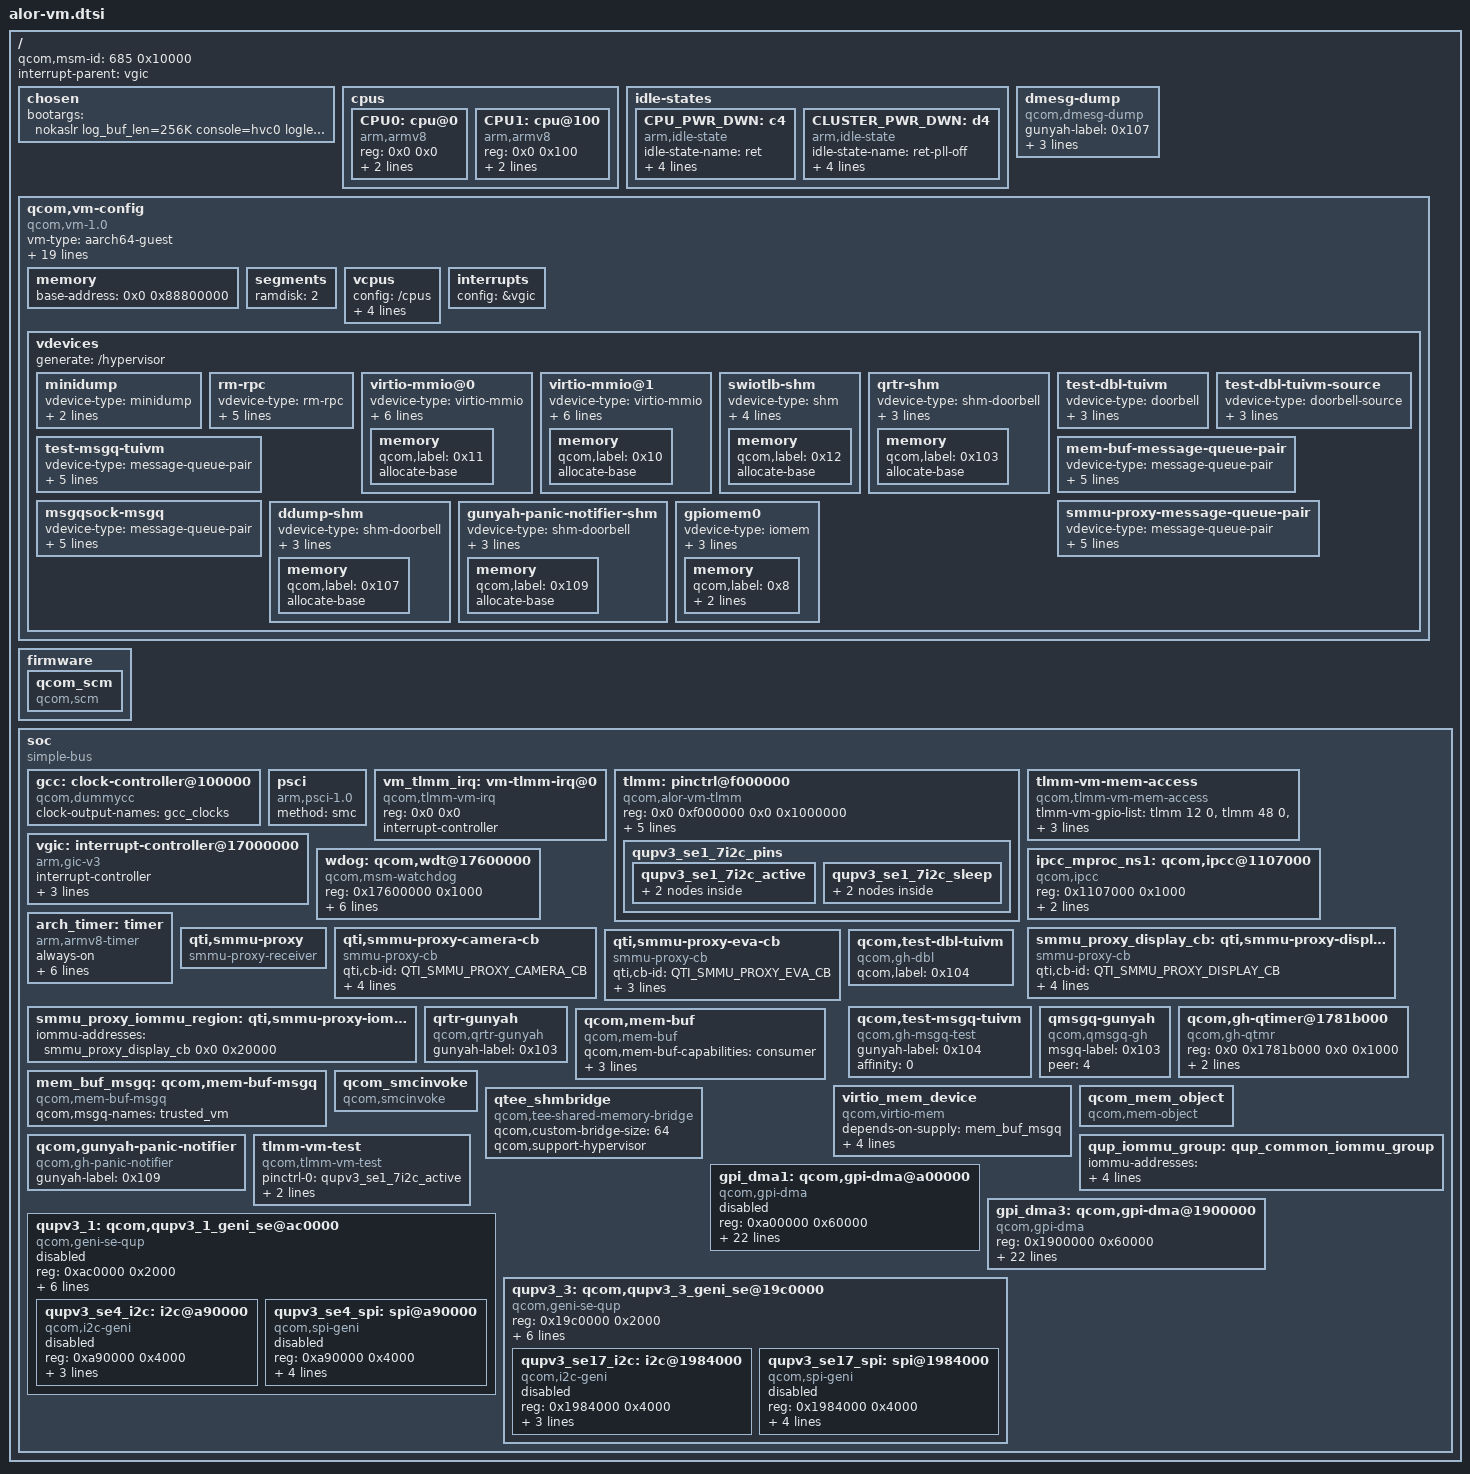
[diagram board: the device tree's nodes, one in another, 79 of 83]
// SPDX-License-Identifier: BSD-3-Clause
/*
 * Copyright (c) Qualcomm Technologies, Inc. and/or its subsidiaries.
 */

#include <dt-bindings/arm/msm/qti-smmu-proxy-dt-ids.h>
#include <dt-bindings/interrupt-controller/arm-gic.h>
#include <dt-bindings/clock/qcom,alor-gcc.h>

/ {
	#address-cells = <0x2>;
	#size-cells = <0x2>;
	qcom,msm-id = <685 0x10000>;
	interrupt-parent = <&vgic>;

	chosen {
		bootargs = "nokaslr log_buf_len=256K console=hvc0 loglevel=8 swiotlb=noforce memhp_default_state=online_movable memory_hotplug.memmap_on_memory=force rcupdate.rcu_expedited=1 rcu_nocbs=0-1 fw_devlink.strict=1 stack_depot_disable=on";
	};

	cpus {
		#address-cells = <0x2>;
		#size-cells = <0x0>;
		CPU0: cpu@0 {
			compatible = "arm,armv8";
			reg = <0x0 0x0>;
			device_type = "cpu";
			enable-method = "psci";
			cpu-idle-states = <&CPU_PWR_DWN
					   &CLUSTER_PWR_DWN>;
		};

		CPU1: cpu@100 {
			compatible = "arm,armv8";
			reg = <0x0 0x100>;
			device_type = "cpu";
			enable-method = "psci";
			cpu-idle-states = <&CPU_PWR_DWN
					   &CLUSTER_PWR_DWN>;
		};
	};

	idle-states {
		CPU_PWR_DWN: c4 {  /* Using Gold C4 latencies */
			compatible = "arm,idle-state";
			idle-state-name = "ret";
			entry-latency-us = <93>;
			exit-latency-us = <129>;
			min-residency-us = <560>;
			arm,psci-suspend-param = <0x00000004>;
		};

		CLUSTER_PWR_DWN: d4 { /* C4+D4 */
			compatible = "arm,idle-state";
			idle-state-name = "ret-pll-off";
			entry-latency-us = <1964>;
			exit-latency-us = <1901>;
			min-residency-us = <24511>;
			arm,psci-suspend-param = <0x0000B354>;
		};
	};

	dmesg-dump {
		compatible = "qcom,dmesg-dump";
		gunyah-label = <0x107>;
		ddump-pubkey-size = <270>;
		ddump-pubkey = /bits/ 8 <0x30 0x82 0x01 0x0a 0x02 0x82 0x01 0x01 0x00 0xe6 0x4b 0x31 0x82 0x61 0x14 0xf2
				0xbe 0xd1 0xe4 0xde 0xe7 0xed 0xba 0x8f 0x3b 0x23 0x5f 0x7a 0xb8 0x16 0x40 0x96
				0xae 0x77 0x5e 0x1b 0xf0 0x3f 0x39 0xab 0x69 0x90 0xb1 0xd4 0x70 0xcb 0x66 0xbc
				0x41 0x08 0x1d 0x37 0xdb 0x49 0xc8 0x49 0x5b 0x99 0x5c 0x32 0xbe 0x62 0xd5 0xa7
				0x3c 0x0f 0xa4 0x4b 0x43 0x49 0xdb 0x54 0x69 0x06 0x0c 0xe5 0x99 0xe5 0xf9 0x1e
				0x25 0x84 0x17 0x47 0x62 0x2b 0x5d 0x0d 0xec 0x5e 0xc6 0xb5 0x86 0xb9 0x75 0x6d
				0xfe 0x7d 0x35 0x4f 0x35 0xc1 0x48 0x10 0x75 0x4c 0x57 0x6b 0x46 0x4b 0xff 0x5b
				0x52 0x22 0x40 0x2c 0xb0 0x47 0xe1 0x47 0xc4 0xe5 0x47 0x0c 0x56 0xe8 0x17 0xd0
				0x7e 0xc3 0x4d 0x9f 0xea 0xd0 0xea 0x87 0xe5 0x51 0x39 0xe8 0x45 0x4c 0x54 0x27
				0x9c 0x50 0x38 0xb7 0x72 0x93 0x12 0x0b 0xa1 0x2f 0x9e 0x04 0x92 0x20 0x6e 0x31
				0x42 0x87 0xe1 0xfe 0x88 0x3f 0xe5 0x09 0xe1 0xf9 0xbe 0x44 0xc6 0xbf 0x10 0x79
				0x36 0x47 0x7b 0xa0 0x8e 0x27 0x31 0xa3 0x70 0x69 0x01 0x54 0x92 0xf4 0x42 0xbd
				0xcd 0x7e 0x79 0x2b 0x2c 0xe1 0xd4 0xba 0x6e 0x34 0xc6 0xe6 0xc6 0x5c 0x63 0xd0
				0x7f 0x39 0x1f 0xe8 0x8d 0x67 0xe6 0x27 0x67 0x0d 0x16 0x57 0x94 0xd1 0xfb 0xdf
				0xce 0xaf 0xfd 0x43 0xb3 0xbe 0x5d 0x83 0x4b 0x93 0x05 0xe8 0xdf 0x04 0xad 0xac
				0xeb 0xa6 0x81 0xa7 0xd5 0x04 0x63 0xbf 0x83 0xb8 0x0c 0xbc 0x20 0x18 0xb5 0x50
				0xd7 0x61 0x84 0x11 0xca 0x2d 0x22 0xb3 0x29 0x02 0x03 0x01 0x00 0x01>;
	};

	qcom,vm-config {
		compatible = "qcom,vm-1.0";
		vm-type = "aarch64-guest";
		boot-config = "fdt,unified";
		os-type = "linux";
		kernel-entry-segment = "kernel";
		kernel-entry-offset = <0x0 0x0>;
		vendor = "QTI";
		image-name = "qcom,trustedvm";
		qcom,pasid = <0x0 0x1c>;
		qcom,qtee-config-info = "p=3,9,39,77,78,7C,8F,97,C8,FE,11B,159,199,47E,7F1,CDF;";
		qcom,secdomain-ids = <45>;
		qcom,primary-vm-index = <0>;
		vm-uri = "vmuid/trusted-ui";
		vm-guid = "598085da-c516-5b25-a9c1-927a02819770";
		qcom,sensitive;

		vwdog = &wdog;
		vm-attrs = "context-dump", "crash-restart";

		iomemory-ranges = <0x0 0x1107000 0x0 0x1107000 0x0 0x1000 0x0
				0x0 0xa24000 0x0 0xa24000 0x0 0x4000 0x0
				0x0 0x1924000 0x0 0x1924000 0x0 0x4000 0x0>;

		/* For LEVM por usecases is QUP1_SE4 and QUP3_SE1.
		 * QUP1_SE4: GPII5 : IRQ_873
		 * QUP3_SE1: GPII5 : IRQ_625
		 */
		gic-irq-ranges = <279 279
				  873 873
				  625 625>; /* PVM->SVM IRQ transfer */

		memory {
			#address-cells = <0x2>;
			#size-cells = <0x0>;
			/*
			 * IPA address linux image is loaded at. Must be within
			 * first 1GB due to memory hotplug requirement.
			 */
			base-address = <0x0 0x88800000 >;
		};

		segments {
			ramdisk = <2>;
		};

		vcpus {
			config = "/cpus";
			affinity = "proxy";
			affinity-map = <0x0 0x0>;
			sched-priority = <0>;       /* relative to PVM */
			sched-timeslice = <2000>;   /* in ms */
		};

		interrupts {
			config = &vgic;
		};

		vdevices {
			generate = "/hypervisor";

			minidump {
				vdevice-type = "minidump";
				push-compatible = "qcom,minidump_rm";
				minidump_allowed;
			};

			rm-rpc {
				vdevice-type = "rm-rpc";
				generate = "/hypervisor/qcom,resource-mgr";
				console-dev;
				message-size = <0x000000f0>;
				queue-depth = <0x00000008>;
				qcom,label = <0x1>;
			};

			virtio-mmio@0 {
				vdevice-type = "virtio-mmio";
				generate = "/virtio-mmio";
				peer-default;
				vqs-num = <0x1>;
				push-compatible = "virtio,mmio";
				dma-coherent;
				dma_base = <0x0 0x0>;
				memory {
					qcom,label = <0x11>;			//for persist.img
					#address-cells = <0x2>;
					allocate-base;
				};
			};

			virtio-mmio@1 {
				vdevice-type = "virtio-mmio";
				generate = "/virtio-mmio";
				peer-default;
				vqs-num = <0x2>;
				push-compatible = "virtio,mmio";
				dma-coherent;
				dma_base = <0x0 0x4000>;
				memory {
					qcom,label = <0x10>;			//for system.img
					#address-cells = <0x2>;
					allocate-base;
				};
			};

			swiotlb-shm {
				vdevice-type = "shm";
				generate = "/swiotlb";
				push-compatible = "swiotlb";
				peer-default;
				dma_base = <0x0 0x8000>;
				memory {
					qcom,label = <0x12>;
					#address-cells = <0x2>;
					allocate-base;
				};
			};

			qrtr-shm {
				vdevice-type = "shm-doorbell";
				generate = "/hypervisor/qrtr-shm";
				push-compatible = "qcom,qrtr-gunyah-gen";
				peer-default;
				memory {
					qcom,label = <0x103>;
					allocate-base;
				};
			};

			test-dbl-tuivm {
				vdevice-type = "doorbell";
				generate = "/hypervisor/test-dbl-tuivm";
				qcom,label = <0x104>;
				peer-default;
			};

			test-dbl-tuivm-source {
				vdevice-type = "doorbell-source";
				generate = "/hypervisor/test-dbl-tuivm-source";
				qcom,label = <0x104>;
				peer-default;
			};

			test-msgq-tuivm {
				vdevice-type = "message-queue-pair";
				generate = "/hypervisor/test-msgq-tuivm-pair";
				message-size = <0xf0>;
				queue-depth = <0x8>;
				qcom,label = <0x104>;
				peer-default;
			};

			mem-buf-message-queue-pair {
				vdevice-type = "message-queue-pair";
				generate = "/hypervisor/membuf-msgq-pair";
				message-size = <0x000000f0>;
				queue-depth = <0x00000008>;
				peer-default;
				qcom,label = <0x101>;
			};

			msgqsock-msgq {
				vdevice-type = "message-queue-pair";
				generate = "/hypervisor/msgqsock-msgq-pair";
				message-size = <0xf0>;
				queue-depth = <0x8>;
				peer = "vm-name:qcom,oemvm";
				qcom,label = <0x103>;
			};

			smmu-proxy-message-queue-pair {
				vdevice-type = "message-queue-pair";
				generate = "/hypervisor/smmu-proxy-msgq-pair";
				message-size = <0x000000f0>;
				queue-depth = <0x00000008>;
				peer-default;
				qcom,label = <0x10A>;
			};

			ddump-shm {
				vdevice-type = "shm-doorbell";
				generate = "/hypervisor/ddump-shm";
				push-compatible = "qcom,ddump-gunyah-gen";
				peer-default;
				memory {
					qcom,label = <0x107>;
					allocate-base;
				};
			};

			gunyah-panic-notifier-shm {
				vdevice-type = "shm-doorbell";
				generate = "/hypervisor/gpn-shm";
				push-compatible = "qcom,gunyah-panic-gen";
				peer-default;
				memory {
					qcom,label = <0x109>;
					allocate-base;
				};
			};

			gpiomem0 {
				vdevice-type = "iomem";
				patch = "/soc/tlmm-vm-mem-access";
				push-compatible = "qcom,tlmm-vm-mem-access";
				peer-default;
				memory {
					qcom,label = <0x8>;
					qcom,mem-info-tag = <0x3>;
					allocate-base;
				};
			};
		};
	};

	firmware: firmware {
		qcom_scm: qcom_scm {
			compatible = "qcom,scm";
		};
	};

	soc: soc { };
};

&soc {
	#address-cells = <1>;
	#size-cells = <1>;
	ranges = <0 0 0 0xffffffff>;
	compatible = "simple-bus";

	gcc: clock-controller@100000 {
		compatible = "qcom,dummycc";
		clock-output-names = "gcc_clocks";
		#clock-cells = <1>;
		#reset-cells = <1>;
	};

	psci {
		compatible = "arm,psci-1.0";
		method = "smc";
	};

	vm_tlmm_irq: vm-tlmm-irq@0 {
		compatible = "qcom,tlmm-vm-irq";
		reg = <0x0 0x0>;
		interrupt-controller;
		#interrupt-cells = <2>;
	};

	tlmm: pinctrl@f000000 {
		compatible = "qcom,alor-vm-tlmm";
		reg = <0x0 0xf000000 0x0 0x1000000>;
		interrupts-extended = <&vm_tlmm_irq 1 IRQ_TYPE_LEVEL_HIGH>;
		gpio-controller;
		#gpio-cells = <2>;
		interrupt-controller;
		#interrupt-cells = <2>;
		/* Valid pins */
		gpios = /bits/ 16 <12 48 49 50 51 68 69 70 71 87 100 128>;
	};

	tlmm-vm-mem-access {
		compatible = "qcom,tlmm-vm-mem-access";
		tlmm-vm-gpio-list = <&tlmm 12 0 &tlmm 48 0 &tlmm 49 0 &tlmm 50 0 &tlmm 51 0
					&tlmm 68 0 &tlmm 69 0 &tlmm 70 0 &tlmm 71 0 &tlmm 87 0
					&tlmm 100 0 &tlmm 128 0>;
	};

	vgic: interrupt-controller@17000000 {
		compatible = "arm,gic-v3";
		interrupt-controller;
		#interrupt-cells = <0x3>;
		#redistributor-regions = <1>;
		redistributor-stride = <0x0 0x40000>;
		reg = <0x17000000 0x10000>,     /* GICD */
		      <0x17080000 0x200000>;    /* GICR * 8 */
	};

	wdog: qcom,wdt@17600000 {
		compatible = "qcom,msm-watchdog";
		reg = <0x17600000 0x1000>;
		reg-names = "wdt-base";
		interrupts = <GIC_SPI 0 IRQ_TYPE_LEVEL_HIGH>,
			<GIC_SPI 1 IRQ_TYPE_LEVEL_HIGH>;
		qcom,bark-time = <11000>;
		qcom,pet-time = <9360>;
		qcom,ipi-ping;
		qcom,wakeup-enable;
	};

	ipcc_mproc_ns1: qcom,ipcc@1107000 {
		compatible = "qcom,ipcc";
		reg = <0x1107000 0x1000>; /* size */
		interrupts = <GIC_SPI 247 IRQ_TYPE_LEVEL_HIGH>;
		interrupt-controller;
		#interrupt-cells = <3>;
		#mbox-cells = <2>;
	};

	arch_timer: timer {
		compatible = "arm,armv8-timer";
		always-on;
		interrupts = <GIC_PPI 13 (GIC_CPU_MASK_SIMPLE(8) | IRQ_TYPE_LEVEL_LOW)>,
			     <GIC_PPI 14 (GIC_CPU_MASK_SIMPLE(8) | IRQ_TYPE_LEVEL_LOW)>,
			     <GIC_PPI 11 (GIC_CPU_MASK_SIMPLE(8) | IRQ_TYPE_LEVEL_LOW)>,
			     <GIC_PPI 12 (GIC_CPU_MASK_SIMPLE(8) | IRQ_TYPE_LEVEL_LOW)>;
		clock-frequency = <19200000>;
	};

	qti,smmu-proxy {
		compatible = "smmu-proxy-receiver";
	};

	qti,smmu-proxy-camera-cb {
		compatible = "smmu-proxy-cb";
		qti,cb-id = <QTI_SMMU_PROXY_CAMERA_CB>;
		qcom,iommu-defer-smr-config;
		iommus = <&apps_smmu 0x1830 0x20>,
			 <&apps_smmu 0x1C10 0x0>,
			 <&apps_smmu 0x18F0 0x0>;
		dma-coherent;
	};

	smmu_proxy_display_cb: qti,smmu-proxy-display-cb {
		compatible = "smmu-proxy-cb";
		qti,cb-id = <QTI_SMMU_PROXY_DISPLAY_CB>;
		qcom,iommu-defer-smr-config;
		memory-region = <&smmu_proxy_iommu_region>;
		iommus = <&apps_smmu 0x801 0x0>;
		dma-coherent;
	};

	qti,smmu-proxy-eva-cb {
		compatible = "smmu-proxy-cb";
		qti,cb-id = <QTI_SMMU_PROXY_EVA_CB>;
		qcom,iommu-defer-smr-config;
		iommus = <&apps_smmu 0x1927 0x0>;
		dma-coherent;
	};

	smmu_proxy_iommu_region: qti,smmu-proxy-iommu-region {
		iommu-addresses = <&smmu_proxy_display_cb 0x0 0x20000>;
	};

	qcom,test-dbl-tuivm {
		compatible = "qcom,gh-dbl";
		qcom,label = <0x104>;
	};

	qcom,test-msgq-tuivm {
		compatible = "qcom,gh-msgq-test";
		gunyah-label = <0x104>;
		affinity = <0>;
	};

	qrtr-gunyah {
		compatible = "qcom,qrtr-gunyah";
		gunyah-label = <0x103>;
	};

	qmsgq-gunyah {
		compatible = "qcom,qmsgq-gh";
		msgq-label = <0x103>;
		peer = <4>;
	};

	qcom,gh-qtimer@1781b000 {
		compatible = "qcom,gh-qtmr";
		reg = <0x0 0x1781b000 0x0 0x1000>;
		reg-names = "qtmr-base";
		interrupts = <GIC_SPI 13 IRQ_TYPE_LEVEL_HIGH>;
		interrupt-names = "qcom,qtmr-intr";
		qcom,secondary;
	};

	qcom,mem-buf {
		compatible = "qcom,mem-buf";
		qcom,mem-buf-capabilities = "consumer";
		qcom,ipa-range = <0x0 0x0 0xf 0xffffffff>;
		qcom,dmabuf-ipa-size = <0x3 0xA0000000>; /* 14GB IPA space for dmabuf */
		qcom,vmid = <45>;
	};

	mem_buf_msgq: qcom,mem-buf-msgq {
		compatible = "qcom,mem-buf-msgq";
		qcom,msgq-names = "trusted_vm";
	};

	virtio_mem_device {
		compatible = "qcom,virtio-mem";
		depends-on-supply = <&mem_buf_msgq>;
		/* Must be memory_block_size_bytes() aligned */
		qcom,max-size = <0x0 0x18000000>;
		qcom,ipa-range = <0x0 0x0 0xf 0xffffffff>;
		qcom,block-size = <0x400000>;
		qcom,initial-movable-zone-size = <0x2000000>;
	};

	qcom_smcinvoke {
		compatible = "qcom,smcinvoke";
	};

	qcom_mem_object {
		compatible = "qcom,mem-object";
	};

	qtee_shmbridge {
		compatible = "qcom,tee-shared-memory-bridge";
		qcom,custom-bridge-size = <64>;
		qcom,support-hypervisor;
	};

	qcom,gunyah-panic-notifier {
		compatible = "qcom,gh-panic-notifier";
		gunyah-label = <0x109>;
	};

	tlmm-vm-test {
		compatible = "qcom,tlmm-vm-test";
		pinctrl-names = "active", "sleep";
		pinctrl-0 = <&qupv3_se1_7i2c_active>;
		pinctrl-1 = <&qupv3_se1_7i2c_sleep>;
		tlmm-vm-gpio-list = <&tlmm 12 0>;
	};

	pinctrl@f000000 {
		qupv3_se1_7i2c_pins: qupv3_se1_7i2c_pins {
			qupv3_se1_7i2c_active: qupv3_se1_7i2c_active {
				mux {
					pins = "gpio12";
					function = "qup2_se3_l0";
				};

				config {
					pins = "gpio12";
					drive-strength = <2>;
					bias-pull-up;
				};
			};

			qupv3_se1_7i2c_sleep: qupv3_se1_7i2c_sleep {
				mux {
					pins = "gpio12";
					function = "gpio";
				};

				config {
					pins = "gpio12";
					drive-strength = <2>;
					bias-disable;
				};
			};
		};
	};

	/*
	 * QUP1 : SE4 - Primary touch
	 * QUP3 : SE1 - Secondary touch
	 */
	qup_iommu_group: qup_common_iommu_group {
		iommu-addresses = <&gpi_dma1 0x00000000 0x00020000>,
				<&qupv3_1 0x00000000 0x00020000>,
				<&gpi_dma3 0x00000000 0x00020000>,
				<&qupv3_3 0x00000000 0x00020000>;
	};

	/* GPI Instance */
	gpi_dma1: qcom,gpi-dma@a00000 {
		compatible = "qcom,gpi-dma";
		#dma-cells = <5>;
		reg = <0xa00000 0x60000>;
		reg-names = "gpi-top";
		iommus = <&apps_smmu 0xb8 0x0>;
		qcom,iommu-group = <&qup_iommu_group>;
		memory-region = <&qup_iommu_group>;
		dma-coherent;
		interrupts = <GIC_SPI 836 IRQ_TYPE_LEVEL_HIGH>,
			<GIC_SPI 837 IRQ_TYPE_LEVEL_HIGH>,
			<GIC_SPI 838 IRQ_TYPE_LEVEL_HIGH>,
			<GIC_SPI 839 IRQ_TYPE_LEVEL_HIGH>,
			<GIC_SPI 840 IRQ_TYPE_LEVEL_HIGH>,
			<GIC_SPI 841 IRQ_TYPE_LEVEL_HIGH>,
			<GIC_SPI 842 IRQ_TYPE_LEVEL_HIGH>,
			<GIC_SPI 843 IRQ_TYPE_LEVEL_HIGH>,
			<GIC_SPI 844 IRQ_TYPE_LEVEL_HIGH>,
			<GIC_SPI 845 IRQ_TYPE_LEVEL_HIGH>,
			<GIC_SPI 846 IRQ_TYPE_LEVEL_HIGH>,
			<GIC_SPI 847 IRQ_TYPE_LEVEL_HIGH>;
		qcom,max-num-gpii = <12>;
		qcom,static-gpii-mask = <0x20>;
		qcom,gpii-mask = <0x0>;
		qcom,ev-factor = <1>;
		qcom,gpi-ee-offset = <0x10000>;
		qcom,le-vm;
		status = "disabled";
	};

	/* QUPv3_1 wrapper instance */
	qupv3_1: qcom,qupv3_1_geni_se@ac0000 {
		compatible = "qcom,geni-se-qup";
		reg = <0xac0000 0x2000>;
		#address-cells = <1>;
		#size-cells = <1>;
		clock-names = "m-ahb", "s-ahb";
		clocks = <&gcc GCC_QUPV3_WRAP_1_M_AXI_CLK>,
			<&gcc GCC_QUPV3_WRAP_1_S_AHB_CLK>;
		iommus = <&apps_smmu 0xb8 0x0>;
		qcom,iommu-group = <&qup_iommu_group>;
		memory-region = <&qup_iommu_group>;
		dma-coherent;
		ranges;
		status = "disabled";

		/* Touchscreen I2C Instance */
		qupv3_se4_i2c: i2c@a90000 {
			compatible = "qcom,i2c-geni";
			reg = <0xa90000 0x4000>;
			#address-cells = <1>;
			#size-cells = <0>;
			dmas = <&gpi_dma1 0 4 3 64 0xc>,
				<&gpi_dma1 1 4 3 64 0xc>;
			dma-names = "tx", "rx";
			qcom,le-vm;
			status = "disabled";
		};

		/* Touchscreen SPI Instance */
		qupv3_se4_spi: spi@a90000 {
			compatible = "qcom,spi-geni";
			reg = <0xa90000 0x4000>;
			#address-cells = <1>;
			#size-cells = <0>;
			reg-names = "se_phys";
			dmas = <&gpi_dma1 0 4 1 64 0xc>,
				<&gpi_dma1 1 4 1 64 0xc>;
			dma-names = "tx", "rx";
			spi-max-frequency = <50000000>;
			qcom,le-vm;
			status = "disabled";
		};
	};

	/* GPI Instance */
	gpi_dma3: qcom,gpi-dma@1900000 {
		compatible = "qcom,gpi-dma";
		#dma-cells = <5>;
		reg = <0x1900000 0x60000>;
		reg-names = "gpi-top";
		iommus = <&apps_smmu 0x4d8 0x0>;
		qcom,iommu-group = <&qup_iommu_group>;
		memory-region = <&qup_iommu_group>;
		dma-coherent;
		interrupts = <GIC_SPI 588 IRQ_TYPE_LEVEL_HIGH>,
			<GIC_SPI 589 IRQ_TYPE_LEVEL_HIGH>,
			<GIC_SPI 590 IRQ_TYPE_LEVEL_HIGH>,
			<GIC_SPI 591 IRQ_TYPE_LEVEL_HIGH>,
			<GIC_SPI 592 IRQ_TYPE_LEVEL_HIGH>,
			<GIC_SPI 593 IRQ_TYPE_LEVEL_HIGH>,
			<GIC_SPI 594 IRQ_TYPE_LEVEL_HIGH>,
			<GIC_SPI 595 IRQ_TYPE_LEVEL_HIGH>,
			<GIC_SPI 596 IRQ_TYPE_LEVEL_HIGH>,
			<GIC_SPI 597 IRQ_TYPE_LEVEL_HIGH>,
			<GIC_SPI 598 IRQ_TYPE_LEVEL_HIGH>,
			<GIC_SPI 599 IRQ_TYPE_LEVEL_HIGH>;
		qcom,max-num-gpii = <12>;
		qcom,static-gpii-mask = <0x20>;
		qcom,gpii-mask = <0x0>;
		qcom,ev-factor = <1>;
		qcom,gpi-ee-offset = <0x10000>;
		qcom,le-vm;
		status = "ok";
	};

	/* QUPv3_3 wrapper instance */
	qupv3_3: qcom,qupv3_3_geni_se@19c0000 {
		compatible = "qcom,geni-se-qup";
		reg = <0x19c0000 0x2000>;
		#address-cells = <1>;
		#size-cells = <1>;
		clock-names = "m-ahb", "s-ahb";
		clocks = <&gcc GCC_QUPV3_WRAP_3_M_AHB_CLK>,
			<&gcc GCC_QUPV3_WRAP_3_S_AHB_CLK>;
		iommus = <&apps_smmu 0x4d8 0x0>;
		qcom,iommu-group = <&qup_iommu_group>;
		memory-region = <&qup_iommu_group>;
		dma-coherent;
		ranges;
		status = "ok";

		/* Touchscreen I2C Instance */
		qupv3_se17_i2c: i2c@1984000 {
			compatible = "qcom,i2c-geni";
			reg = <0x1984000 0x4000>;
			#address-cells = <1>;
			#size-cells = <0>;
			dmas = <&gpi_dma3 0 1 3 64 0xc>,
				<&gpi_dma3 1 1 3 64 0xc>;
			dma-names = "tx", "rx";
			qcom,le-vm;
			status = "disabled";
		};

		/* Touchscreen SPI Instance */
		qupv3_se17_spi: spi@1984000 {
			compatible = "qcom,spi-geni";
			reg = <0x1984000 0x4000>;
			#address-cells = <1>;
			#size-cells = <0>;
			reg-names = "se_phys";
			dmas = <&gpi_dma3 0 1 1 64 0xc>,
				<&gpi_dma3 1 1 1 64 0xc>;
			dma-names = "tx", "rx";
			spi-max-frequency = <50000000>;
			qcom,le-vm;
			status = "disabled";
		};
	};
};

#include "msm-arm-smmu-alor-vm.dtsi"
#include "alor-vm-dma-heaps.dtsi"
